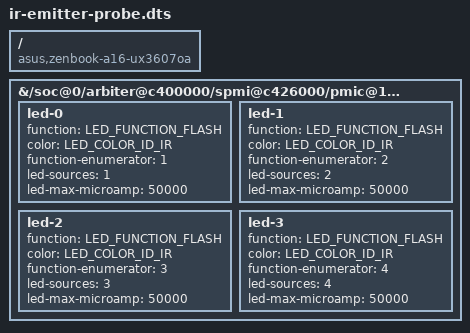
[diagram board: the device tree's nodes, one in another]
// IR flood emitter, stage 1 (channel discovery).
// Selected by hardware.asus-zenbook-a16.irEmitter.stage = "probe" (modules/ir-emitter.nix).
// Do not raise these currents.
//
// PMH0101 (SPMI bus 0, SID 1) flash LED module at 0xee00, leds-qcom-flash.
// Each of the four channels as its own torch-only IR LED, so each can be
// lit alone or together from /sys/class/leds. No flash-max-microamp: no
// flash mode, no v4l2-flash.
//
// Currents: led-max-microamp is per LED here (one channel each), 50 mA.
// The driver also writes it to the module's TORCH_CLAMP register
// ((50 mA / 5 mA) - 1 = 9), a hardware cap of 50 mA per channel in
// torch mode. Torch has no safety timer: turn it off by hand.
/dts-v1/;
/plugin/;

#include <dt-bindings/leds/common.h>

/ {
	compatible = "asus,zenbook-a16-ux3607oa";
};

&{/soc@0/arbiter@c400000/spmi@c426000/pmic@1/led-controller@ee00} {
	status = "okay";

	led-0 {
		function = LED_FUNCTION_FLASH;
		color = <LED_COLOR_ID_IR>;
		function-enumerator = <1>;
		led-sources = <1>;
		led-max-microamp = <50000>;
	};

	led-1 {
		function = LED_FUNCTION_FLASH;
		color = <LED_COLOR_ID_IR>;
		function-enumerator = <2>;
		led-sources = <2>;
		led-max-microamp = <50000>;
	};

	led-2 {
		function = LED_FUNCTION_FLASH;
		color = <LED_COLOR_ID_IR>;
		function-enumerator = <3>;
		led-sources = <3>;
		led-max-microamp = <50000>;
	};

	led-3 {
		function = LED_FUNCTION_FLASH;
		color = <LED_COLOR_ID_IR>;
		function-enumerator = <4>;
		led-sources = <4>;
		led-max-microamp = <50000>;
	};
};
